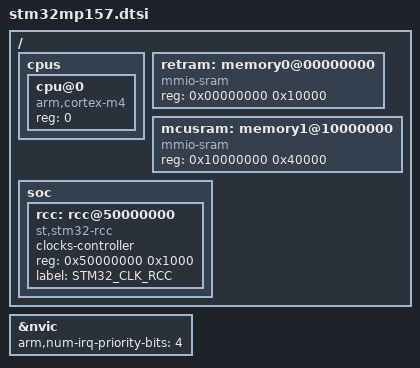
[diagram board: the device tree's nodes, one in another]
/*
 * Copyright (c) 2017 Linaro Limited
 *
 * SPDX-License-Identifier: Apache-2.0
 */

#include <arm/armv7-m.dtsi>
#include <dt-bindings/clock/stm32_clock.h>

/ {
	cpus {
		#address-cells = <1>;
		#size-cells = <0>;

		cpu@0 {
			device_type = "cpu";
			compatible = "arm,cortex-m4";
			reg = <0>;
		};
	};

	retram: memory0@00000000 {
		device_type = "memory";
		compatible = "mmio-sram";
		reg = <0x00000000 0x10000>;
	};
	mcusram: memory1@10000000 {
		device_type = "memory";
		compatible = "mmio-sram";
		reg = <0x10000000 0x40000>;
	};

	soc {
		rcc: rcc@50000000 {
			compatible = "st,stm32-rcc";
			clocks-controller;
			#clocks-cells = <2>;
			reg = <0x50000000 0x1000>;
			label = "STM32_CLK_RCC";
		};

	};
};

&nvic {
	arm,num-irq-priority-bits = <4>;
};
